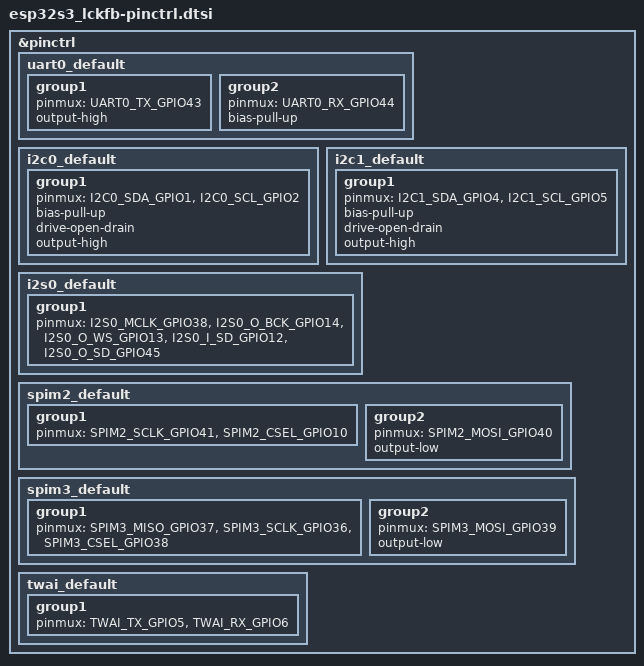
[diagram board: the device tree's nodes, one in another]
/*
 * Copyright (c) 2022 Espressif Systems (Shanghai) Co., Ltd.
 *
 * SPDX-License-Identifier: Apache-2.0
 */

#include <zephyr/dt-bindings/pinctrl/esp-pinctrl-common.h>
#include <dt-bindings/pinctrl/esp32s3-pinctrl.h>
#include <zephyr/dt-bindings/pinctrl/esp32s3-gpio-sigmap.h>

&pinctrl {
	uart0_default: uart0_default {
		group1 {
			pinmux = <UART0_TX_GPIO43>;
			output-high;
		};

		group2 {
			pinmux = <UART0_RX_GPIO44>;
			bias-pull-up;
		};
	};

	i2c0_default: i2c0_default {
		group1 {
			pinmux = <I2C0_SDA_GPIO1>,
					 <I2C0_SCL_GPIO2>;
			bias-pull-up;
			drive-open-drain;
			output-high;
		};
	};

	i2c1_default: i2c1_default {
		group1 {
			pinmux = <I2C1_SDA_GPIO4>,
					 <I2C1_SCL_GPIO5>;
			bias-pull-up;
			drive-open-drain;
			output-high;
		};
	};

	i2s0_default: i2s0_default {
		group1 {
			pinmux = <I2S0_MCLK_GPIO38>,   /* Master clock (if using I2S MCLK out) */
					 <I2S0_O_BCK_GPIO14>,   /* Bit clock */
					 <I2S0_O_WS_GPIO13>,     /* Word select / frame sync */
					 <I2S0_I_SD_GPIO12>,    /* Data in (from codec to MCU) */
					 <I2S0_O_SD_GPIO45>;   /* Data out (from MCU to codec) */
		};
	};

	spim2_default: spim2_default {
		group1 {
			pinmux = <SPIM2_SCLK_GPIO41>,
					 <SPIM2_CSEL_GPIO10>;
		};

		group2 {
			pinmux = <SPIM2_MOSI_GPIO40>;
			output-low;
		};
	};

	spim3_default: spim3_default {
		group1 {
			pinmux = <SPIM3_MISO_GPIO37>,
					 <SPIM3_SCLK_GPIO36>,
					 <SPIM3_CSEL_GPIO38>;
		};

		group2 {
			pinmux = <SPIM3_MOSI_GPIO39>;
			output-low;
		};
	};

	twai_default: twai_default {
		group1 {
			pinmux = <TWAI_TX_GPIO5>,
					 <TWAI_RX_GPIO6>;
		};
	};
};
